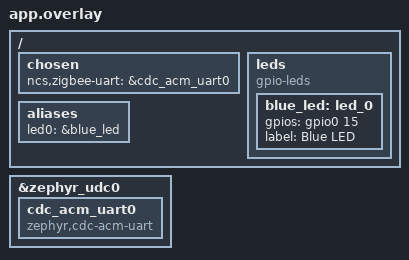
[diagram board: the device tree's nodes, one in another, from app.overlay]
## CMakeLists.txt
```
cmake_minimum_required(VERSION 3.20.0)

find_package(Zephyr REQUIRED HINTS $ENV{ZEPHYR_BASE})
project(zigbee_ncp)

target_sources(app PRIVATE src/main.c)
```

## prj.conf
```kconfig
# Внутренний RC-генератор (на SuperMini нет внешнего кварца 32.768 кГц)
CONFIG_CLOCK_CONTROL_NRF_K32SRC_RC=y
CONFIG_CLOCK_CONTROL_NRF_K32SRC_XTAL=n
CONFIG_CLOCK_CONTROL_NRF_K32SRC_500PPM=y

# Сборка UF2 для загрузчика Adafruit
CONFIG_BUILD_OUTPUT_UF2=y

# Криптография для стека Zigbee (ZBOSS) — исправляет ошибку zb_nrf_crypto.c
CONFIG_CRYPTO=y
CONFIG_CRYPTO_NRF_ECB=y
CONFIG_ENTROPY_GENERATOR=y

# Роль координатора
CONFIG_ZIGBEE_ROLE_COORDINATOR=y

# Увеличенная память и хранилище NVRAM (устраняет падение адаптера при подключении роутера)
CONFIG_FLASH=y
CONFIG_FLASH_MAP=y
CONFIG_NVS=y
CONFIG_SETTINGS=y
CONFIG_HEAP_MEM_POOL_SIZE=16384
CONFIG_MAIN_STACK_SIZE=4096
CONFIG_SYSTEM_WORKQUEUE_STACK_SIZE=4096

# Виртуальный COM-порт через USB (CDC ACM)
CONFIG_USB_DEVICE_STACK=y
CONFIG_USB_DEVICE_PRODUCT="SuperMini Zigbee Coordinator"
CONFIG_USB_CDC_ACM=y
CONFIG_UART_LINE_CTRL=y
CONFIG_UART_INTERRUPT_DRIVEN=y

# Отключаем логи и консоль в USB
CONFIG_LOG=n
CONFIG_CONSOLE=n
CONFIG_UART_CONSOLE=n
```

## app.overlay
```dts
/ {
    chosen {
        ncs,zigbee-uart = &cdc_acm_uart0;
    };

    leds {
        compatible = "gpio-leds";
        blue_led: led_0 {
            gpios = <&gpio0 15 GPIO_ACTIVE_HIGH>;
            label = "Blue LED";
        };
    };

    aliases {
        led0 = &blue_led;
    };
};

&zephyr_udc0 {
    cdc_acm_uart0: cdc_acm_uart0 {
        compatible = "zephyr,cdc-acm-uart";
    };
};
```

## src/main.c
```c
#include <zephyr/kernel.h>
#include <zephyr/device.h>
#include <zephyr/drivers/gpio.h>
#include <zephyr/drivers/uart.h>
#include <zephyr/sys/ring_buffer.h>
#include <zephyr/usb/usb_device.h>
#include <zboss_api.h>
#include <zb_osif.h>
#include <zb_nrf_platform.h>

static const struct device *uart_dev = DEVICE_DT_GET(DT_CHOSEN(zigbee_uart));
static const struct gpio_dt_spec led = GPIO_DT_SPEC_GET(DT_ALIAS(led0), gpios);

static serial_send_data_cb_t send_cb = NULL;
static serial_recv_data_cb_t recv_cb = NULL;

RING_BUF_DECLARE(rx_ringbuf, 1024);
RING_BUF_DECLARE(tx_ringbuf, 1024);

static void uart_irq_handler(const struct device *dev, void *user_data)
{
    ARG_UNUSED(user_data);

    while (uart_irq_update(dev) && uart_irq_is_pending(dev)) {
        if (uart_irq_rx_ready(dev)) {
            uint8_t buf;
            int len = uart_fifo_read(dev, buf, sizeof(buf));
            if (len > 0) {
                ring_buf_put(&rx_ringbuf, buf, len);
                if (recv_cb != NULL) {
                    recv_cb(buf, (zb_ushort_t)len);
                }
            }
        }

        if (uart_irq_tx_ready(dev)) {
            uint8_t buf;
            uint32_t len = ring_buf_get(&tx_ringbuf, buf, sizeof(buf));
            if (len > 0) {
                int sent = uart_fifo_fill(dev, buf, len);
                if (sent < (int)len) {
                    /* Если USB FIFO заполнился, остаток уйдет в следующем прерывании */
                }
            } else {
                uart_irq_tx_disable(dev);
            }
        }
    }
}

void zb_osif_serial_set_cb_send_data(serial_send_data_cb_t cb)
{
    send_cb = cb;
}

void zb_osif_serial_set_cb_recv_data(serial_recv_data_cb_t cb)
{
    recv_cb = cb;
    if (device_is_ready(uart_dev)) {
        uart_irq_callback_user_data_set(uart_dev, uart_irq_handler, NULL);
        uart_irq_rx_enable(uart_dev);
    }
}

void zb_osif_serial_send_data(zb_uint8_t *buf, zb_ushort_t len)
{
    if (!device_is_ready(uart_dev)) {
        return;
    }

    ring_buf_put(&tx_ringbuf, buf, len);
    uart_irq_tx_enable(uart_dev);

    if (send_cb != NULL) {
        send_cb(len);
    }
}

void zb_osif_serial_recv_data(zb_uint8_t *buf, zb_ushort_t len)
{
    ring_buf_get(&rx_ringbuf, buf, len);
}

int main(void)
{
    if (gpio_is_ready_dt(&led)) {
        gpio_pin_configure_dt(&led, GPIO_OUTPUT_ACTIVE);
    }

    int ret = usb_enable(NULL);
    if (ret != 0 && ret != -EALREADY) {
        return 0;
    }

    k_sleep(K_SECONDS(2));

    if (gpio_is_ready_dt(&led)) {
        gpio_pin_set_dt(&led, 0);
    }

    zigbee_enable();

    while (1) {
        k_sleep(K_FOREVER);
    }

    return 0;
}
```
